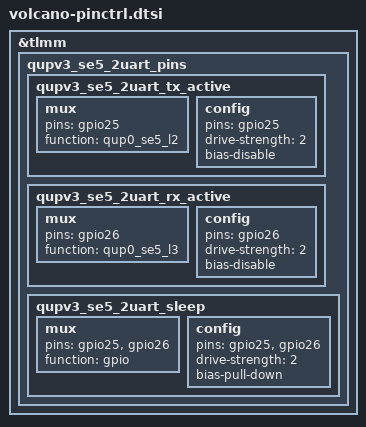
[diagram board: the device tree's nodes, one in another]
&tlmm {
	qupv3_se5_2uart_pins: qupv3_se5_2uart_pins {
		qupv3_se5_2uart_tx_active: qupv3_se5_2uart_tx_active {
			mux {
				pins = "gpio25";
				function = "qup0_se5_l2";
			};

			config {
				pins = "gpio25";
				drive-strength = <2>;
				bias-disable;
			};
		};

		qupv3_se5_2uart_rx_active: qupv3_se5_2uart_rx_active {
			mux {
				pins = "gpio26";
				function = "qup0_se5_l3";
			};

			config {
				pins = "gpio26";
				drive-strength = <2>;
				bias-disable;
			};
		};

		qupv3_se5_2uart_sleep: qupv3_se5_2uart_sleep {
			mux {
				pins = "gpio25", "gpio26";
				function = "gpio";
			};

			config {
				pins = "gpio25", "gpio26";
				drive-strength = <2>;
				bias-pull-down;
			};
		};
	};
};
